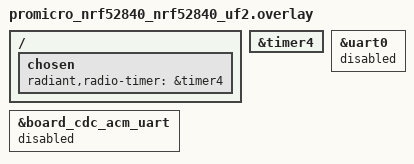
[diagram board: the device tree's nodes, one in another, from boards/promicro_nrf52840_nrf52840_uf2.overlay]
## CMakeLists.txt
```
# SPDX-License-Identifier: Apache-2.0

cmake_minimum_required(VERSION 3.20.0)

# This sample lives inside the module, so it finds the module by relative path.
# In your own project, point this at wherever RadiANT's radiant/ directory is.
list(APPEND ZEPHYR_EXTRA_MODULES "${CMAKE_CURRENT_SOURCE_DIR}/../..")

find_package(Zephyr REQUIRED HINTS $ENV{ZEPHYR_BASE})
project(hr_transmitter)

target_sources(app PRIVATE src/main.c)
```

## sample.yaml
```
# SPDX-License-Identifier: Apache-2.0

sample:
  name: RadiANT heart-rate transmitter
common:
  tags:
    - radiant
  build_only: true
tests:
  sample.radiant.hr_transmitter:
    platform_allow:
      - native_sim
      - nrf52840dk/nrf52840
      - nrf54l15dk/nrf54l15/cpuapp
      - promicro_nrf52840/nrf52840/uf2
    integration_platforms:
      - native_sim
      - nrf52840dk/nrf52840
```

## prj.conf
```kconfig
# SPDX-License-Identifier: Apache-2.0

CONFIG_RADIANT=y
CONFIG_RADIANT_ANTR_API=y

CONFIG_LOG=y
```

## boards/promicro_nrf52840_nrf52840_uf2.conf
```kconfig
# SPDX-License-Identifier: Apache-2.0

# The board would otherwise bring up USB for a serial console this sample
# does not use.
CONFIG_BOARD_SERIAL_BACKEND_CDC_ACM=n
```

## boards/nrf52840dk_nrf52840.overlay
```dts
/* SPDX-License-Identifier: Apache-2.0 */
/*
 * The timer RadiANT's nRF backend uses. It needs five compare channels, which
 * on nRF52 means TIMER3 or TIMER4.
 */
/ {
	chosen {
		radiant,radio-timer = &timer4;
	};
};

&timer4 {
	status = "okay";
};
```

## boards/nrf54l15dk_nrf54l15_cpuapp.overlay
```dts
/* SPDX-License-Identifier: Apache-2.0 */
/* The timer RadiANT's nRF backend uses. */
/ {
	chosen {
		radiant,radio-timer = &timer20;
	};
};

&timer20 {
	status = "okay";
};
```

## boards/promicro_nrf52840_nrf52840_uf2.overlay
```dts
/* SPDX-License-Identifier: Apache-2.0 */
/*
 * The Pro Micro board's default console is USB CDC-ACM, which this sample does
 * not need, so the sample runs with no console at all. Confirm it with any ANT+
 * receiver.
 */
/ {
	chosen {
		/delete-property/ zephyr,console;
		/delete-property/ zephyr,shell-uart;
		/delete-property/ zephyr,uart-mcumgr;
		/delete-property/ zephyr,bt-mon-uart;
		/delete-property/ zephyr,bt-c2h-uart;

		radiant,radio-timer = &timer4;
	};
};

&timer4 {
	status = "okay";
};

&board_cdc_acm_uart {
	status = "disabled";
};

&uart0 {
	status = "disabled";
};
```

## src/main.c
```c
/* SPDX-License-Identifier: Apache-2.0 */
/*
 * Broadcast a simulated ANT+ heart rate of 120 bpm.
 *
 * Any ANT+ compatible receiver will see this as a heart-rate strap, including
 * a second board running the hr_receiver sample.
 */

#include <zephyr/kernel.h>

#include <radiant/ant_radio.h>

#define HR_CHANNEL     0u
#define HR_NETWORK     0u
#define HR_DEVICE_TYPE 0x78u
#define HR_PERIOD      8070u /* 32768 / 8070 = 4.06 messages a second */
#define HR_RF_FREQ     57u   /* 2457 MHz */

/* Pick your own, from 1 to 65535. Two sensors should not share a number. */
#define DEVICE_NUMBER  12345u
#define TX_TYPE        5u

#define SIM_BPM        120u
#define SIM_BEAT_MS    (60000u / SIM_BPM)

/* The ANT+ network key. Without it nothing can hear this channel. */
static const uint8_t ant_plus_key[8] = {
	0xB9, 0xA5, 0x21, 0xFB, 0xBD, 0x72, 0xC3, 0x45
};

static void send_next_page(void)
{
	uint32_t beats = k_uptime_get_32() / SIM_BEAT_MS;
	/* The time of the last beat, in 1/1024 s. */
	uint16_t event_time = (uint16_t)(beats * SIM_BEAT_MS * 1024u / 1000u);
	/* HR data page 0. */
	uint8_t page[8] = {
		0x00u, 0xFFu, 0xFFu, 0xFFu,
		(uint8_t)event_time, (uint8_t)(event_time >> 8),
		(uint8_t)beats, SIM_BPM,
	};

	(void)antr_broadcast_message_tx(HR_CHANNEL, sizeof(page), page);
}

/*
 * Called by RadiANT for every message. EVENT_TX means a page has just gone out,
 * which is the moment to supply the next one.
 */
void antr_on_message(const struct antr_msg *msg)
{
	if (msg->id == ANTW_MESG_RESPONSE_EVENT_ID &&
	    msg->len >= ANTW_MESG_RESPONSE_EVENT_SIZE &&
	    msg->data[0] == HR_CHANNEL && msg->data[2] == ANTW_EVENT_TX) {
		send_next_page();
	}
}

#define TRY(call)                                                        \
	do {                                                             \
		antr_err_t rc = (call);                                  \
		if (rc != ANTW_RESPONSE_NO_ERROR) {                      \
			printk("%s failed: 0x%02x\n", #call, rc);        \
			return 0;                                        \
		}                                                        \
	} while (0)

int main(void)
{
	TRY(antr_init());
	TRY(antr_network_address_set(HR_NETWORK, ant_plus_key));

	TRY(antr_channel_assign(HR_CHANNEL, ANTW_CHANNEL_TYPE_MASTER, HR_NETWORK, 0u));
	TRY(antr_channel_id_set(HR_CHANNEL, DEVICE_NUMBER, HR_DEVICE_TYPE, TX_TYPE));
	TRY(antr_channel_period_set(HR_CHANNEL, HR_PERIOD));
	TRY(antr_channel_radio_freq_set(HR_CHANNEL, HR_RF_FREQ));
	/* The first message goes out empty; EVENT_TX after it starts the data. */
	TRY(antr_channel_open(HR_CHANNEL));

	printk("Transmitting as device %u\n", DEVICE_NUMBER);
	return 0;
}
```
